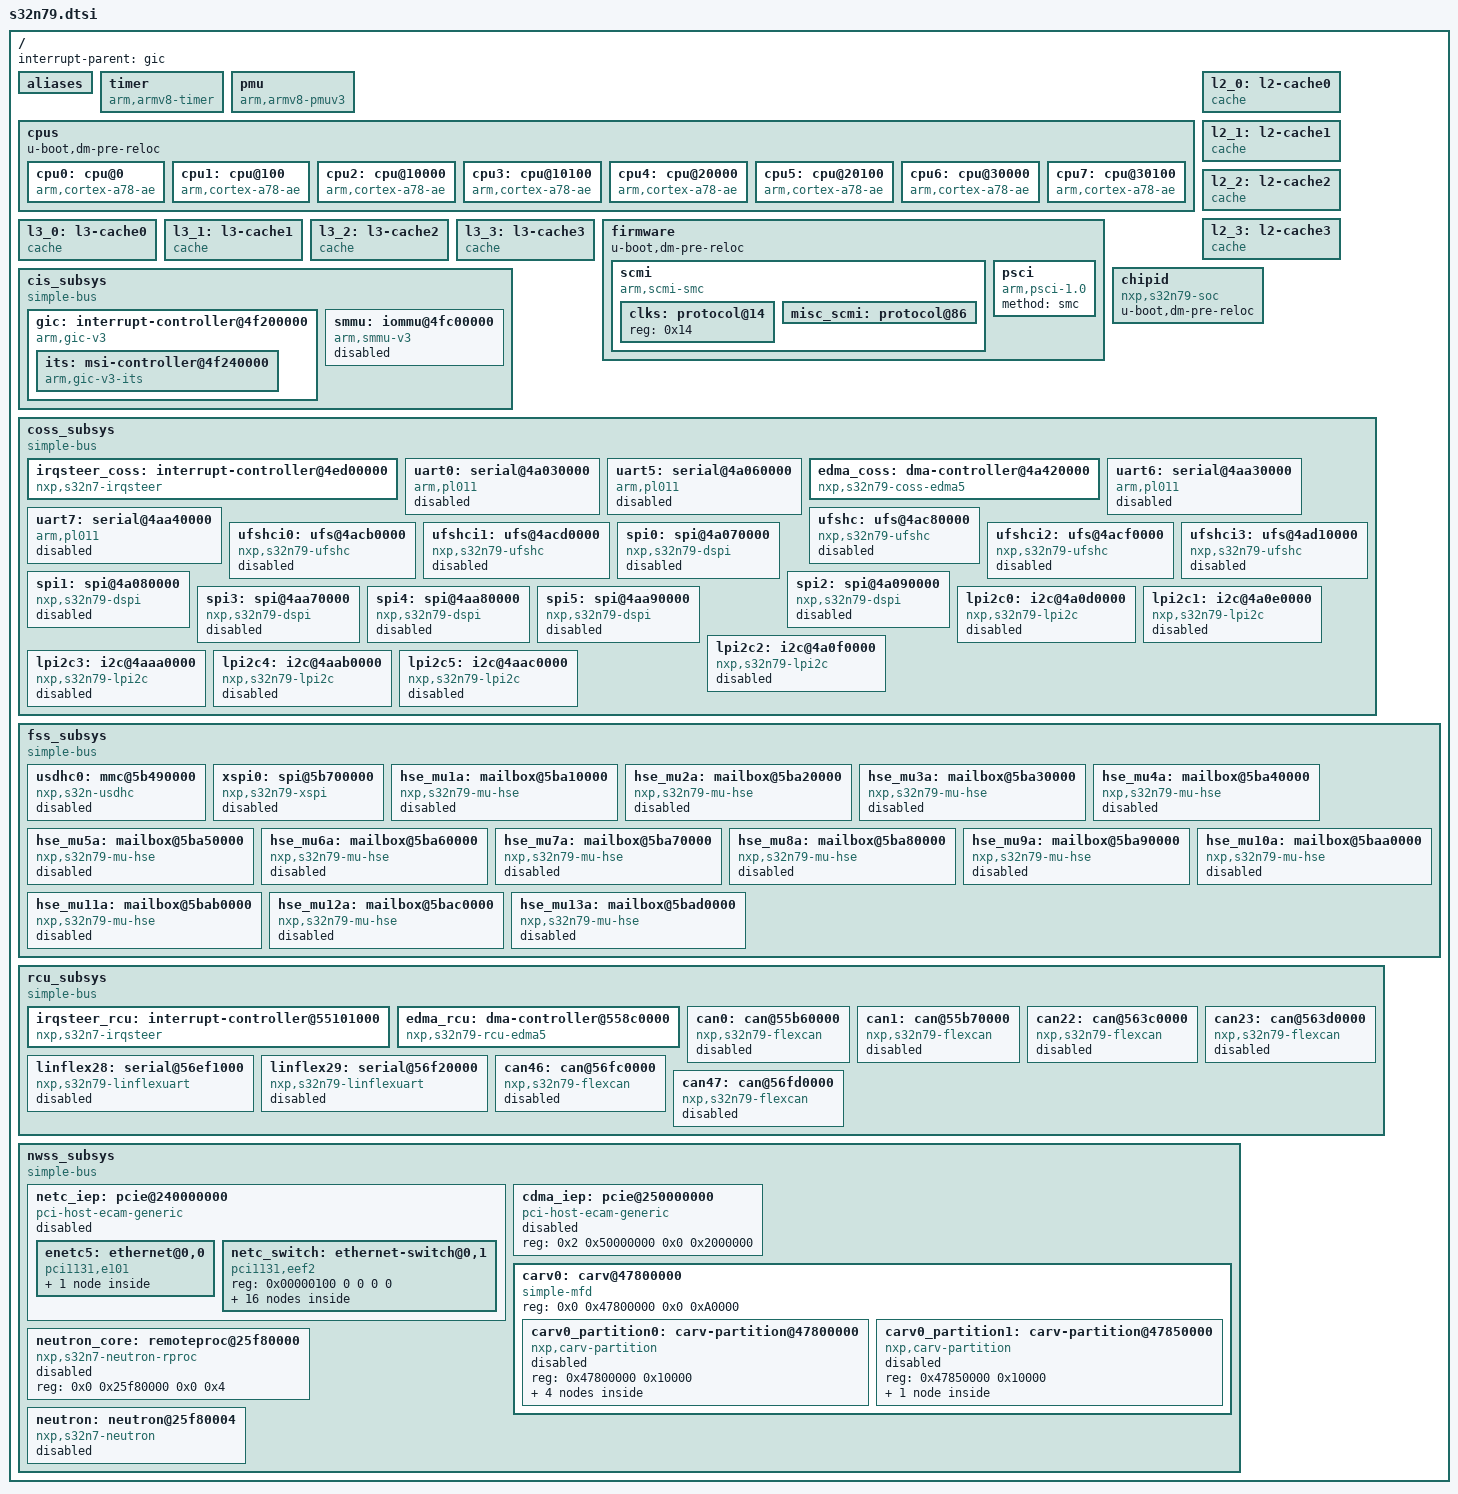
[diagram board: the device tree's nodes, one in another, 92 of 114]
// SPDX-License-Identifier: (GPL-2.0+ OR BSD-3-Clause)
/*
 * Device Tree Include file for NXP S32N79 SoC.
 *
 * Copyright 2024-2026 NXP
 */

#include <dt-bindings/interrupt-controller/arm-gic.h>
#include <dt-bindings/memory/s32n7-carv.h>

/ {
	interrupt-parent = <&gic>;
	#address-cells = <2>;
	#size-cells = <2>;

	aliases {
		serial0 = &uart0;
		serial5 = &uart5;
		serial6 = &uart6;
		serial7 = &uart7;
		serial28 = &linflex28;
		serial29 = &linflex29;
		mmc0 = &usdhc0;
		spi0 = &spi0;
		spi1 = &spi1;
		spi2 = &spi2;
		spi3 = &spi3;
		spi4 = &spi4;
		spi5 = &spi5;
		spi6 = &xspi0;
	};

	timer: timer {
		compatible = "arm,armv8-timer";
		interrupts = <GIC_PPI 13 IRQ_TYPE_LEVEL_LOW>,
			     <GIC_PPI 14 IRQ_TYPE_LEVEL_LOW>,
			     <GIC_PPI 11 IRQ_TYPE_LEVEL_LOW>,
			     <GIC_PPI 10 IRQ_TYPE_LEVEL_LOW>;
	};

	pmu {
		compatible = "arm,armv8-pmuv3";
		interrupt-parent = <&gic>;
		interrupts = <GIC_PPI 7 IRQ_TYPE_LEVEL_HIGH>;
	};

	cpus {
		#address-cells = <1>;
		#size-cells = <0>;
		u-boot,dm-pre-reloc;

		cpu0: cpu@0 {
			device_type = "cpu";
			compatible = "arm,cortex-a78-ae";
			reg = <0x0>;
			enable-method = "psci";
			next-level-cache = <&l2_0>;
			u-boot,dm-pre-reloc;
		};

		cpu1: cpu@100 {
			device_type = "cpu";
			compatible = "arm,cortex-a78-ae";
			reg = <0x100>;
			enable-method = "psci";
			next-level-cache = <&l2_0>;
			u-boot,dm-pre-reloc;
		};

		cpu2: cpu@10000 {
			device_type = "cpu";
			compatible = "arm,cortex-a78-ae";
			reg = <0x10000>;
			enable-method = "psci";
			next-level-cache = <&l2_1>;
			u-boot,dm-pre-reloc;
		};

		cpu3: cpu@10100 {
			device_type = "cpu";
			compatible = "arm,cortex-a78-ae";
			reg = <0x10100>;
			enable-method = "psci";
			next-level-cache = <&l2_1>;
			u-boot,dm-pre-reloc;
		};

		cpu4: cpu@20000 {
			device_type = "cpu";
			compatible = "arm,cortex-a78-ae";
			reg = <0x20000>;
			enable-method = "psci";
			next-level-cache = <&l2_2>;
			u-boot,dm-pre-reloc;
		};

		cpu5: cpu@20100 {
			device_type = "cpu";
			compatible = "arm,cortex-a78-ae";
			reg = <0x20100>;
			enable-method = "psci";
			next-level-cache = <&l2_2>;
			u-boot,dm-pre-reloc;
		};

		cpu6: cpu@30000 {
			device_type = "cpu";
			compatible = "arm,cortex-a78-ae";
			reg = <0x30000>;
			enable-method = "psci";
			next-level-cache = <&l2_3>;
			u-boot,dm-pre-reloc;
		};

		cpu7: cpu@30100 {
			device_type = "cpu";
			compatible = "arm,cortex-a78-ae";
			reg = <0x30100>;
			enable-method = "psci";
			next-level-cache = <&l2_3>;
			u-boot,dm-pre-reloc;
		};
	};

	l2_0: l2-cache0 {
		compatible = "cache";
		cache-level = <2>;
		cache-size = <524288>;
		cache-line-size = <64>;
		cache-sets = <512>;
		next-level-cache = <&l3_0>;
	};

	l2_1: l2-cache1 {
		compatible = "cache";
		cache-level = <2>;
		cache-size = <524288>;
		cache-line-size = <64>;
		cache-sets = <512>;
		next-level-cache = <&l3_1>;
	};

	l2_2: l2-cache2 {
		compatible = "cache";
		cache-level = <2>;
		cache-size = <524288>;
		cache-line-size = <64>;
		cache-sets = <512>;
		next-level-cache = <&l3_2>;
	};

	l2_3: l2-cache3 {
		compatible = "cache";
		cache-level = <2>;
		cache-size = <524288>;
		cache-line-size = <64>;
		cache-sets = <512>;
		next-level-cache = <&l3_3>;
	};

	l3_0: l3-cache0 {
		compatible = "cache";
		cache-level = <3>;
		cache-size = <1048576>;
		cache-line-size = <64>;
		cache-sets = <1024>;
	};

	l3_1: l3-cache1 {
		compatible = "cache";
		cache-level = <3>;
		cache-size = <1048576>;
		cache-line-size = <64>;
		cache-sets = <1024>;
	};

	l3_2: l3-cache2 {
		compatible = "cache";
		cache-level = <3>;
		cache-size = <1048576>;
		cache-line-size = <64>;
		cache-sets = <1024>;
	};

	l3_3: l3-cache3 {
		compatible = "cache";
		cache-level = <3>;
		cache-size = <1048576>;
		cache-line-size = <64>;
		cache-sets = <1024>;
	};

	firmware {
		u-boot,dm-pre-reloc;

		scmi: scmi {
			u-boot,dm-pre-reloc;
			compatible = "arm,scmi-smc";
			mbox-names = "tx";
			shmem = <&scmi_shbuf>;
			arm,smc-id = <0xc20000fe>;
			#address-cells = <1>;
			#size-cells = <0>;
			status = "okay";

			clks: protocol@14 {
				reg = <0x14>;
				#clock-cells = <0x01>;
			};

			misc_scmi: protocol@86 {
				u-boot,dm-pre-reloc;
				reg = <0x86>;
			};
		};

		psci {
			compatible = "arm,psci-1.0";
			method = "smc";
		};
	};

	chipid: chipid {
		u-boot,dm-pre-reloc;
		compatible = "nxp,s32n79-soc";
	};

	cis_subsys {
		compatible = "simple-bus";
		#address-cells = <1>;
		#size-cells = <1>;
		ranges = <0x0 0x0 0x0 0x20000000>,
			 <0x4f200000 0x0 0x4f200000 0xc00000>;

		gic: interrupt-controller@4f200000 {
			compatible = "arm,gic-v3";
			#address-cells = <1>;
			#size-cells = <1>;
			#interrupt-cells = <3>;
			interrupt-controller;
			interrupts = <GIC_PPI 9 IRQ_TYPE_LEVEL_HIGH>;
			reg = <0x4f200000 0x10000>, /* GIC Dist */
			      <0x4f260000 0x100000>; /* GICR (RD_base + SGI_base) */
			ranges;

			its: msi-controller@4f240000 {
				compatible = "arm,gic-v3-its";
				reg = <0x4f240000 0x20000>;
				dma-coherent;
				msi-controller;
			};
		};

		smmu: iommu@4fc00000 {
			compatible = "arm,smmu-v3";
			reg = <0x4fc00000 0x200000>;
			interrupt-parent = <&gic>;
			interrupts = <GIC_SPI 1 IRQ_TYPE_EDGE_RISING>,
				     <GIC_SPI 4 IRQ_TYPE_EDGE_RISING>,
				     <GIC_SPI 8 IRQ_TYPE_EDGE_RISING>,
				     <GIC_SPI 2 IRQ_TYPE_EDGE_RISING>;
			interrupt-names = "eventq", "gerror", "priq", "cmdq-sync";
			#iommu-cells = <1>;
			dma-coherent;
			status = "disabled";
		};
	};

	coss_subsys {
		compatible = "simple-bus";
		#address-cells = <1>;
		#size-cells = <1>;
		ranges = <0x4a000000 0x0 0x4a000000 0xff0000>,
			 <0x4e000000 0x0 0x4e000000 0x1000000>;

		irqsteer_coss: interrupt-controller@4ed00000 {
			compatible = "nxp,s32n7-irqsteer";
			reg = <0x4ed00000 0x10000>;
			interrupts = <GIC_SPI 527 IRQ_TYPE_LEVEL_HIGH>,
					<GIC_SPI 528 IRQ_TYPE_LEVEL_HIGH>,
					<GIC_SPI 529 IRQ_TYPE_LEVEL_HIGH>,
					<GIC_SPI 530 IRQ_TYPE_LEVEL_HIGH>,
					<GIC_SPI 531 IRQ_TYPE_LEVEL_HIGH>,
					<GIC_SPI 532 IRQ_TYPE_LEVEL_HIGH>,
					<GIC_SPI 533 IRQ_TYPE_LEVEL_HIGH>,
					<GIC_SPI 534 IRQ_TYPE_LEVEL_HIGH>;
			interrupt-controller;
			interrupt-parent = <&gic>;
			#interrupt-cells = <1>;
			clocks = <&clks 0x9a>;
			clock-names = "ipg";
			fsl,channel = <0>;
			fsl,num-irqs = <512>;
		};

		uart0: serial@4a030000 {
			compatible = "arm,pl011", "arm,primecell";
			reg = <0x4a030000 0x1000>;
			clocks = <&clks 0x9a>, <&clks 0x9a>;
			clock-names = "uartclk", "apb_pclk";
			interrupt-parent = <&irqsteer_coss>;
			interrupts = <264>;
			status = "disabled";
		};

		uart5: serial@4a060000 {
			compatible = "arm,pl011", "arm,primecell";
			reg = <0x4a060000 0x1000>;
			clocks = <&clks 0x9a>, <&clks 0x9a>;
			clock-names = "uartclk", "apb_pclk";
			interrupt-parent = <&irqsteer_coss>;
			interrupts = <269>;
			status = "disabled";
		};

		edma_coss: dma-controller@4a420000 {
			compatible = "nxp,s32n79-coss-edma5";
			reg = <0x4a420000 0x201000>,
				<0x4a410000 0x1000>,
				<0x4a414000 0x1000>,
				<0x4a418000 0x1000>,
				<0x4a41c000 0x1000>;
			#dma-cells = <2>;
			dma-channels = <32>;
			interrupt-parent = <&irqsteer_coss>;
			/* Two DMA channels share the same interrupt. */
			interrupts = <0>, <0>, <1>, <1>,
				     <2>, <2>, <3>, <3>,
				     <4>, <4>, <5>, <5>,
				     <6>, <6>, <7>, <7>,
				     <8>, <8>, <9>, <9>,
				     <10>, <10>, <11>, <11>,
				     <12>, <12>, <13>, <13>,
				     <14>, <14>, <15>, <15>,
				     <448>;
			clocks = <&clks 0x90>, <&clks 0x9a>,
				<&clks 0x90>, <&clks 0x9a>;
			/* dmamux0 - axi ; dmamux1 - ipg */
			clock-names = "dmamux0", "dmamux1", "dmamux2", "dmamux3";
		};

		uart6: serial@4aa30000 {
			compatible = "arm,pl011", "arm,primecell";
			reg = <0x4aa30000 0x1000>;
			clocks = <&clks 0x9a>, <&clks 0x9a>;
			clock-names = "uartclk", "apb_pclk";
			interrupt-parent = <&irqsteer_coss>;
			interrupts = <270>;
			status = "disabled";
		};

		uart7: serial@4aa40000 {
			compatible = "arm,pl011", "arm,primecell";
			reg = <0x4aa40000 0x1000>;
			clocks = <&clks 0x9a>, <&clks 0x9a>;
			clock-names = "uartclk", "apb_pclk";
			interrupt-parent = <&irqsteer_coss>;
			interrupts = <271>;
			status = "disabled";
		};

		ufshc: ufs@4ac80000 {
			compatible = "nxp,s32n79-ufshc", "jedec,ufs-3.0";
			reg = <0x4ac80000 0x1000>, <0x4ac40000 0x1000>;
			reg-names = "ufshc", "scm";
			interrupt-parent = <&irqsteer_coss>;
			interrupts = <211>;
			clocks = <&clks 0x91>;
			clock-names = "core_clk";
			status = "disabled";
			iommus = <&smmu 0x2>;
		};

		ufshci0: ufs@4acb0000 {
			compatible = "nxp,s32n79-ufshc", "jedec,ufs-3.0";
			reg = <0x4acb0000 0x1000>;
			reg-names = "ufshc";
			interrupt-parent = <&irqsteer_coss>;
			interrupts = <212>;
			iommus = <&smmu 0x10>;
			status = "disabled";
		};

		ufshci1: ufs@4acd0000 {
			compatible = "nxp,s32n79-ufshc", "jedec,ufs-3.0";
			reg = <0x4acd0000 0x1000>;
			reg-names = "ufshc";
			interrupt-parent = <&irqsteer_coss>;
			interrupts = <213>;
			iommus = <&smmu 0x11>;
			status = "disabled";
		};

		ufshci2: ufs@4acf0000 {
			compatible = "nxp,s32n79-ufshc", "jedec,ufs-3.0";
			reg = <0x4acf0000 0x1000>;
			reg-names = "ufshc";
			interrupt-parent = <&irqsteer_coss>;
			interrupts = <214>;
			iommus = <&smmu 0x12>;
			status = "disabled";
		};

		ufshci3: ufs@4ad10000 {
			compatible = "nxp,s32n79-ufshc", "jedec,ufs-3.0";
			reg = <0x4ad10000 0x1000>;
			reg-names = "ufshc";
			interrupt-parent = <&irqsteer_coss>;
			interrupts = <215>;
			iommus = <&smmu 0x13>;
			status = "disabled";
		};

		spi0: spi@4a070000 {
			compatible = "nxp,s32n79-dspi";
			reg = <0x4a070000 0x1000>;
			interrupt-parent = <&irqsteer_coss>;
			interrupts = <272>;
			clocks = <&clks 0x9c>;
			clock-names = "dspi";
			spi-num-chipselects = <6>;
			bus-num = <0>;
			spi-fifo-size = <16>;
			spi-cpol;
			spi-cpha;
			status = "disabled";
		};

		spi1: spi@4a080000 {
			compatible = "nxp,s32n79-dspi";
			reg = <0x4a080000 0x1000>;
			interrupt-parent = <&irqsteer_coss>;
			interrupts = <273>;
			clocks = <&clks 0x9c>;
			clock-names = "dspi";
			spi-num-chipselects = <6>;
			bus-num = <1>;
			spi-fifo-size = <16>;
			spi-cpol;
			spi-cpha;
			status = "disabled";
		};

		spi2: spi@4a090000 {
			compatible = "nxp,s32n79-dspi";
			reg = <0x4a090000 0x1000>;
			interrupt-parent = <&irqsteer_coss>;
			interrupts = <274>;
			clocks = <&clks 0x9c>;
			clock-names = "dspi";
			spi-num-chipselects = <6>;
			bus-num = <2>;
			spi-fifo-size = <16>;
			spi-cpol;
			spi-cpha;
			status = "disabled";
		};

		spi3: spi@4aa70000 {
			compatible = "nxp,s32n79-dspi";
			reg = <0x4aa70000 0x1000>;
			interrupt-parent = <&irqsteer_coss>;
			interrupts = <275>;
			clocks = <&clks 0x9c>;
			clock-names = "dspi";
			spi-num-chipselects = <6>;
			bus-num = <3>;
			spi-fifo-size = <16>;
			spi-cpol;
			spi-cpha;
			status = "disabled";
		};

		spi4: spi@4aa80000 {
			compatible = "nxp,s32n79-dspi";
			reg = <0x4aa80000 0x1000>;
			interrupt-parent = <&irqsteer_coss>;
			interrupts = <276>;
			clocks = <&clks 0x9c>;
			clock-names = "dspi";
			spi-num-chipselects = <6>;
			bus-num = <4>;
			spi-fifo-size = <16>;
			spi-cpol;
			spi-cpha;
			status = "disabled";
		};

		spi5: spi@4aa90000 {
			compatible = "nxp,s32n79-dspi";
			reg = <0x4aa90000 0x1000>;
			interrupt-parent = <&irqsteer_coss>;
			interrupts = <277>;
			clocks = <&clks 0x9c>;
			clock-names = "dspi";
			spi-num-chipselects = <3>;
			bus-num = <5>;
			spi-fifo-size = <16>;
			spi-cpol;
			spi-cpha;
			status = "disabled";
		};

		lpi2c0: i2c@4a0d0000 {
			compatible = "nxp,s32n79-lpi2c";
			reg = <0x4a0d0000 0x1000>;
			clocks = <&clks 0x9a>, <&clks 0x9a>;
			clock-names = "per", "ipg";
			interrupt-parent = <&irqsteer_coss>;
			interrupts = <256>;
			status = "disabled";
		};

		lpi2c1: i2c@4a0e0000 {
			compatible = "nxp,s32n79-lpi2c";
			reg = <0x4a0e0000 0x1000>;
			clocks = <&clks 0x9a>, <&clks 0x9a>;
			clock-names = "per", "ipg";
			interrupt-parent = <&irqsteer_coss>;
			interrupts = <257>;
			status = "disabled";
		};

		lpi2c2: i2c@4a0f0000 {
			compatible = "nxp,s32n79-lpi2c";
			reg = <0x4a0f0000 0x1000>;
			clocks = <&clks 0x9a>, <&clks 0x9a>;
			clock-names = "per", "ipg";
			interrupt-parent = <&irqsteer_coss>;
			interrupts = <258>;
			status = "disabled";
		};

		lpi2c3: i2c@4aaa0000 {
			compatible = "nxp,s32n79-lpi2c";
			reg = <0x4aaa0000 0x1000>;
			clocks = <&clks 0x9a>, <&clks 0x9a>;
			clock-names = "per", "ipg";
			interrupt-parent = <&irqsteer_coss>;
			interrupts = <259>;
			status = "disabled";
		};

		lpi2c4: i2c@4aab0000 {
			compatible = "nxp,s32n79-lpi2c";
			reg = <0x4aab0000 0x1000>;
			clocks = <&clks 0x9a>, <&clks 0x9a>;
			clock-names = "per", "ipg";
			interrupt-parent = <&irqsteer_coss>;
			interrupts = <260>;
			status = "disabled";
		};

		lpi2c5: i2c@4aac0000 {
			compatible = "nxp,s32n79-lpi2c";
			reg = <0x4aac0000 0x1000>;
			clocks = <&clks 0x9a>, <&clks 0x9a>;
			clock-names = "per", "ipg";
			interrupt-parent = <&irqsteer_coss>;
			interrupts = <261>;
			status = "disabled";
		};
	};

	fss_subsys {
		compatible = "simple-bus";
		#address-cells = <1>;
		#size-cells = <1>;
		ranges = <0x10000000 0x0 0x10000000 0x10000000>,
			 <0x5b490000 0x0 0x5b490000 0x1000>,
			 <0x5b700000 0x0 0x5b700000 0x81000>,
			 <0x5ba00000 0x0 0x5ba00000 0x1000000>;

		usdhc0: mmc@5b490000 {
			compatible = "nxp,s32n-usdhc";
			reg = <0x5b490000 0x1000>;
			interrupts = <GIC_SPI 472 IRQ_TYPE_LEVEL_HIGH>;
			clocks = <&clks 0x58>, <&clks 0x50>, <&clks 0x5f>;
			clock-names = "ipg", "ahb", "per";
			bus-width = <8>;
			clock-frequency = <0>;	/* updated dynamically if 0 */
			status = "disabled";
			iommus = <&smmu 0x1>;
		};

		xspi0: spi@5b700000 {
			compatible = "nxp,s32n79-xspi";
			reg = <0x5b700000 0x81000>, <0x10000000 0x10000000>;
			reg-names = "base", "mmap";
			interrupts = <GIC_SPI 367 IRQ_TYPE_LEVEL_HIGH>;// EENV0
			#address-cells = <1>;
			#size-cells = <0>;
			clocks = <&clks 0x5c>;
			clock-names = "per";
			status = "disabled";
		};

		hse_mu1a: mailbox@5ba10000 {
			compatible = "nxp,s32n79-mu-hse";
			reg = <0x5ba10000 0x1000>;
			interrupts = <GIC_SPI 329 IRQ_TYPE_LEVEL_HIGH>,
				     <GIC_SPI 330 IRQ_TYPE_LEVEL_HIGH>;
			status = "disabled";
			secure-status = "disabled";
		};

		hse_mu2a: mailbox@5ba20000 {
			compatible = "nxp,s32n79-mu-hse";
			reg = <0x5ba20000 0x1000>;
			interrupts = <GIC_SPI 331 IRQ_TYPE_LEVEL_HIGH>,
				     <GIC_SPI 332 IRQ_TYPE_LEVEL_HIGH>;
			status = "disabled";
			secure-status = "disabled";
		};

		hse_mu3a: mailbox@5ba30000 {
			compatible = "nxp,s32n79-mu-hse";
			reg = <0x5ba30000 0x1000>;
			interrupts = <GIC_SPI 333 IRQ_TYPE_LEVEL_HIGH>,
				     <GIC_SPI 334 IRQ_TYPE_LEVEL_HIGH>;
			status = "disabled";
			secure-status = "disabled";
		};

		hse_mu4a: mailbox@5ba40000 {
			compatible = "nxp,s32n79-mu-hse";
			reg = <0x5ba40000 0x1000>;
			interrupts = <GIC_SPI 335 IRQ_TYPE_LEVEL_HIGH>,
				     <GIC_SPI 336 IRQ_TYPE_LEVEL_HIGH>;
			status = "disabled";
			secure-status = "disabled";
		};

		hse_mu5a: mailbox@5ba50000 {
			compatible = "nxp,s32n79-mu-hse";
			reg = <0x5ba50000 0x1000>;
			interrupts = <GIC_SPI 337 IRQ_TYPE_LEVEL_HIGH>,
				     <GIC_SPI 338 IRQ_TYPE_LEVEL_HIGH>;
			status = "disabled";
			secure-status = "disabled";
		};

		hse_mu6a: mailbox@5ba60000 {
			compatible = "nxp,s32n79-mu-hse";
			reg = <0x5ba60000 0x1000>;
			interrupts = <GIC_SPI 339 IRQ_TYPE_LEVEL_HIGH>,
				     <GIC_SPI 340 IRQ_TYPE_LEVEL_HIGH>;
			status = "disabled";
			secure-status = "disabled";
		};

		hse_mu7a: mailbox@5ba70000 {
			compatible = "nxp,s32n79-mu-hse";
			reg = <0x5ba70000 0x1000>;
			interrupts = <GIC_SPI 341 IRQ_TYPE_LEVEL_HIGH>,
				     <GIC_SPI 342 IRQ_TYPE_LEVEL_HIGH>;
			status = "disabled";
			secure-status = "disabled";
		};

		hse_mu8a: mailbox@5ba80000 {
			compatible = "nxp,s32n79-mu-hse";
			reg = <0x5ba80000 0x1000>;
			interrupts = <GIC_SPI 343 IRQ_TYPE_LEVEL_HIGH>,
				     <GIC_SPI 344 IRQ_TYPE_LEVEL_HIGH>;
			status = "disabled";
			secure-status = "disabled";
		};

		hse_mu9a: mailbox@5ba90000 {
			compatible = "nxp,s32n79-mu-hse";
			reg = <0x5ba90000 0x1000>;
			interrupts = <GIC_SPI 345 IRQ_TYPE_LEVEL_HIGH>,
				     <GIC_SPI 346 IRQ_TYPE_LEVEL_HIGH>;
			status = "disabled";
			secure-status = "disabled";
		};

		hse_mu10a: mailbox@5baa0000 {
			compatible = "nxp,s32n79-mu-hse";
			reg = <0x5baa0000 0x1000>;
			interrupts = <GIC_SPI 347 IRQ_TYPE_LEVEL_HIGH>,
				     <GIC_SPI 348 IRQ_TYPE_LEVEL_HIGH>;
			status = "disabled";
			secure-status = "disabled";
		};

		hse_mu11a: mailbox@5bab0000 {
			compatible = "nxp,s32n79-mu-hse";
			reg = <0x5bab0000 0x1000>;
			interrupts = <GIC_SPI 349 IRQ_TYPE_LEVEL_HIGH>,
				     <GIC_SPI 350 IRQ_TYPE_LEVEL_HIGH>;
			status = "disabled";
			secure-status = "disabled";
		};

		hse_mu12a: mailbox@5bac0000 {
			compatible = "nxp,s32n79-mu-hse";
			reg = <0x5bac0000 0x1000>;
			interrupts = <GIC_SPI 351 IRQ_TYPE_LEVEL_HIGH>,
				     <GIC_SPI 352 IRQ_TYPE_LEVEL_HIGH>;
			status = "disabled";
			secure-status = "disabled";
		};

		hse_mu13a: mailbox@5bad0000 {
			compatible = "nxp,s32n79-mu-hse";
			reg = <0x5bad0000 0x1000>;
			interrupts = <GIC_SPI 353 IRQ_TYPE_LEVEL_HIGH>,
				     <GIC_SPI 354 IRQ_TYPE_LEVEL_HIGH>;
			status = "disabled";
			secure-status = "disabled";
		};
	};

	rcu_subsys {
		compatible = "simple-bus";
		#address-cells = <1>;
		#size-cells = <1>;
		ranges = <0x54000000 0x0 0x54000000 0x4000000>;

		irqsteer_rcu: interrupt-controller@55101000 {
			compatible = "nxp,s32n7-irqsteer";
			reg = <0x55101000 0x1000>;
			interrupts = <GIC_SPI 73 IRQ_TYPE_LEVEL_HIGH>,
				     <GIC_SPI 74 IRQ_TYPE_LEVEL_HIGH>,
				     <GIC_SPI 75 IRQ_TYPE_LEVEL_HIGH>,
				     <GIC_SPI 76 IRQ_TYPE_LEVEL_HIGH>,
				     <GIC_SPI 77 IRQ_TYPE_LEVEL_HIGH>,
				     <GIC_SPI 78 IRQ_TYPE_LEVEL_HIGH>,
				     <GIC_SPI 79 IRQ_TYPE_LEVEL_HIGH>,
				     <GIC_SPI 80 IRQ_TYPE_LEVEL_HIGH>;
			interrupt-controller;
			interrupt-parent = <&gic>;
			#interrupt-cells = <1>;
			clocks = <&clks 0xf9>;
			clock-names = "ipg";
			fsl,channel = <0>;
			fsl,num-irqs = <512>;
		};

		edma_rcu: dma-controller@558c0000 {
			compatible = "nxp,s32n79-rcu-edma5";
			reg = <0x558c0000 0x101000>,
				<0x558b1000 0x1000>,
				<0x558b0000 0x1000>;
			#dma-cells = <2>;
			dma-channels = <16>;
			interrupt-parent = <&irqsteer_rcu>;
			interrupts = <192>, <193>, <194>, <195>,
				     <196>, <197>, <198>, <199>,
				     <200>, <201>, <202>, <203>,
				     <204>, <205>, <206>, <207>,
				     <384>;
			clocks = <&clks 0xf8>, <&clks 0xf9>;
			/* dmamux0 - aix ; dmamux1 - ipg */
			clock-names = "dmamux0", "dmamux1";
		};

		can0: can@55b60000 {
			compatible = "nxp,s32n79-flexcan";
			reg = <0x55b60000 0x4000>;
			interrupt-parent = <&irqsteer_rcu>;
			interrupts = <0>, <64>;
			interrupt-names = "mb_0-127", "berr";
			/* CANFD_PE_CLK */
			clocks = <&clks 0xf9>, <&clks 0xfc>;
			clock-names = "ipg", "per";
			status = "disabled";
		};

		can1: can@55b70000 {
			compatible = "nxp,s32n79-flexcan";
			reg = <0x55b70000 0x4000>;
			interrupt-parent = <&irqsteer_rcu>;
			interrupts = <1>, <65>;
			interrupt-names = "mb_0-127", "berr";
			/* CANFD_PE_CLK */
			clocks = <&clks 0xf9>, <&clks 0xfc>;
			clock-names = "ipg", "per";
			status = "disabled";
		};

		can22: can@563c0000 {
			compatible = "nxp,s32n79-flexcan";
			reg = <0x563c0000 0x4000>;
			interrupt-parent = <&irqsteer_rcu>;
			interrupts = <22>, <86>;
			interrupt-names = "mb_0-127", "berr";
			/* CANFD_PE_CLK */
			clocks = <&clks 0xf9>, <&clks 0xfc>;
			clock-names = "ipg", "per";
			status = "disabled";
		};

		can23: can@563d0000 {
			compatible = "nxp,s32n79-flexcan";
			reg = <0x563d0000 0x4000>;
			interrupt-parent = <&irqsteer_rcu>;
			interrupts = <23>, <87>;
			interrupt-names = "mb_0-127", "berr";
			/* CANFD_PE_CLK */
			clocks = <&clks 0xf9>, <&clks 0xfc>;
			clock-names = "ipg", "per";
			status = "disabled";
		};

		linflex28: serial@56ef1000 {
			compatible = "nxp,s32n79-linflexuart",
					"fsl,s32v234-linflexuart";
			reg = <0x56ef1000 0x1000>;
			interrupts = <188>;
			interrupt-parent = <&irqsteer_rcu>;
			clocks = <&clks 0x100>, <&clks 0xff>;
			clock-names = "lin", "ipg";
			dmas = <&edma_rcu 1 53>,
				<&edma_rcu 0 53>;
			dma-names = "rx", "tx";
			status = "disabled";
		};

		linflex29: serial@56f20000 {
			compatible = "nxp,s32n79-linflexuart",
					"fsl,s32v234-linflexuart";
			reg = <0x56f20000 0x1000>;
			interrupts = <189>;
			interrupt-parent = <&irqsteer_rcu>;
			clocks = <&clks 0x100>, <&clks 0xff>;
			clock-names = "lin", "ipg";
			dmas = <&edma_rcu 1 54>,
			       <&edma_rcu 0 54>;
			dma-names = "rx", "tx";
			status = "disabled";
		};

		can46: can@56fc0000 {
			compatible = "nxp,s32n79-flexcan";
			reg = <0x56fc0000 0x4000>;
			interrupt-parent = <&irqsteer_rcu>;
			interrupts = <46>, <110>;
			interrupt-names = "mb_0-127", "berr";
			/* CANFD_PE_CLK */
			clocks = <&clks 0xf9>, <&clks 0xfc>;
			clock-names = "ipg", "per";
			status = "disabled";
		};

		can47: can@56fd0000 {
			compatible = "nxp,s32n79-flexcan";
			reg = <0x56fd0000 0x4000>;
			interrupt-parent = <&irqsteer_rcu>;
			interrupts = <47>, <111>;
			interrupt-names = "mb_0-127", "berr";
			/* CANFD_PE_CLK */
			clocks = <&clks 0xf9>, <&clks 0xfc>;
			clock-names = "ipg", "per";
			status = "disabled";
		};
	};

	nwss_subsys {
		compatible = "simple-bus";
		#address-cells = <2>;
		#size-cells = <2>;
		ranges = <0x0 0x47800000 0x0 0x47800000 0x0 0x1540000>,
			 <0x2 0x40000000 0x2 0x40000000 0x0 0x2000000>,
			 <0x0 0x25f80000 0x0 0x25f80000 0x0 0x100000>;

		netc_iep: pcie@240000000 {
			compatible = "pci-host-ecam-generic";
			reg = <0x2 0x40e00000 0x0 0x100000>;
			#address-cells = <3>;
			#size-cells = <2>;
			msi-parent = <&its>;
			device_type = "pci";
			bus-range = <0x0 0x0>;
			status = "disabled";

			ranges = /* SW0 */
				 <0x82000000 0x0 0x48800000 0x0 0x48800000 0x0 0x80000>,
				 /* ENETC5 */
				 <0x82000000 0x0 0x489c0000 0x0 0x489c0000 0x0 0x40000>,
				 /* EMDIO0 */
				 <0x82000000 0x0 0x48a40000 0x0 0x48a40000 0x0 0x20000>,
				 /* SW0 MSI-X */
				 <0x82000000 0x0 0x48a80000 0x0 0x48a80000 0x0 0x10000>,
				 /* EMDIO0 MSI-X */
				 <0x82000000 0x0 0x48ab0000 0x0 0x48ab0000 0x0 0x10000>,
				 /* VSI14 */
				 <0x82000000 0x0 0x48bb0000 0x0 0x48bb0000 0x0 0x10000>,
				 /* VSI14 MSI-X */
				 <0x82000000 0x0 0x48ca0000 0x0 0x48ca0000 0x0 0x10000>;

			enetc5: ethernet@0,0 {
				compatible = "pci1131,e101";
				reg = <0x00000000 0 0 0 0>;
				phy-mode = "internal";

				fixed-link {
					speed = <2500>;
					full-duplex;
					pause;
				};
			};

			netc_switch: ethernet-switch@0,1 {
				compatible = "pci1131,eef2", "nxp,s32n79-netc-switch";
				reg = <0x00000100 0 0 0 0>;

				netc_switch_ports: ports {
					#address-cells = <1>;
					#size-cells = <0>;

					/* External ports */
					netc_switch_port0: port@0 {
						reg = <0>;
						label = "lan0";
						status = "disabled";
					};

					netc_switch_port1: port@1 {
						reg = <1>;
						label = "lan1";
						status = "disabled";
					};

					port@2 {
						reg = <2>;
						label = "lan2";
						status = "disabled";
					};

					port@3 {
						reg = <3>;
						label = "lan3";
						status = "disabled";
					};

					port@4 {
						reg = <4>;
						label = "lan4";
						status = "disabled";
					};

					port@5 {
						reg = <5>;
						label = "lan5";
						status = "disabled";
					};

					port@6 {
						reg = <6>;
						label = "lan6";
						status = "disabled";
					};

					port@7 {
						reg = <7>;
						label = "lan7";
						status = "disabled";
					};

					/* Internal ports */
					port@8 {
						reg = <8>;
						label = "sw8";
						status = "disabled";
					};

					port@9 {
						reg = <9>;
						label = "sw9";
						status = "disabled";
					};

					port@10 {
						reg = <10>;
						label = "sw10";
						status = "disabled";
					};

					port@11 {
						reg = <11>;
						label = "sw11";
						status = "disabled";
					};

					port@12 {
						reg = <12>;
						label = "sw12";
						status = "disabled";
					};

					netc_switch_port13: port@13 {
						reg = <13>;
						label = "cpu13";
						phy-mode = "internal";
						ethernet = <&enetc5>;

						fixed-link {
							speed = <2500>;
							full-duplex;
						};
					};
				};
			};
		};

		cdma_iep: pcie@250000000 {
			compatible = "pci-host-ecam-generic";
			reg = <0x2 0x50000000 0x0 0x2000000>;
			#address-cells = <3>;
			#size-cells = <2>;
			device_type = "pci";
			status = "disabled";

			ranges = <0x82000000 0x0 0x48000000 0x0 0x48000000 0x0 0x620000>;
		};

		carv0: carv@47800000 {
			compatible = "simple-mfd";
			reg = <0x0 0x47800000 0x0 0xA0000>;
			ranges = <0x47800000 0x0 0x47800000 0xA0000>;
			#address-cells = <1>;
			#size-cells = <1>;

			carv0_partition0: carv-partition@47800000 {
				compatible = "nxp,carv-partition", "simple-mfd";
				reg = <0x47800000 0x10000>;
				ranges = <0x47800000 0x47800000 0x50000>;
				#address-cells = <1>;
				#size-cells = <1>;
				status = "disabled";

				carv0_partition0_user0: carv-user@47810000 {
					compatible = "nxp,carv-uio";
					reg = <0x47810000 0x10000>;
					interrupts = <GIC_SPI 251 IRQ_TYPE_LEVEL_HIGH>;
					status = "disabled";
				};

				carv0_partition0_user1: carv-user@47820000 {
					compatible = "nxp,carv-uio";
					reg = <0x47820000 0x10000>;
					interrupts = <GIC_SPI 253 IRQ_TYPE_LEVEL_HIGH>;
					status = "disabled";
				};

				carv0_partition0_user2: carv-user@47830000 {
					compatible = "nxp,carv-uio";
					reg = <0x47830000 0x10000>;
					interrupts = <GIC_SPI 255 IRQ_TYPE_LEVEL_HIGH>;
					status = "disabled";
				};

				carv0_partition0_user3: carv-user@47840000 {
					compatible = "nxp,carv-uio";
					reg = <0x47840000 0x10000>;
					interrupts = <GIC_SPI 257 IRQ_TYPE_LEVEL_HIGH>;
					status = "disabled";
				};
			};

			carv0_partition1: carv-partition@47850000 {
				compatible = "nxp,carv-partition", "simple-mfd";
				reg = <0x47850000 0x10000>;
				ranges = <0x47850000 0x47850000 0x50000>;
				#address-cells = <1>;
				#size-cells = <1>;
				status = "disabled";

				carv0_partition1_user0: carv-user@47860000 {
					compatible = "nxp,carvnet-rproc";
					reg = <0x47860000 0x10000>;
					interrupts = <GIC_SPI 259 IRQ_TYPE_LEVEL_HIGH>;
					status = "disabled";
				};
			};
		};

		neutron_core: remoteproc@25f80000 {
			compatible = "nxp,s32n7-neutron-rproc";
			reg = <0x0 0x25f80000 0x0 0x4>;
			status = "disabled";
		};

		neutron: neutron@25f80004 {
			compatible = "nxp,s32n7-neutron";
			reg = <0x0 0x25f80004 0x0 0x400>;
			fsl,neutron-rproc = <&neutron_core>;
			interrupts = <GIC_SPI 269 IRQ_TYPE_LEVEL_HIGH>;
			status = "disabled";
		};
	};
};
